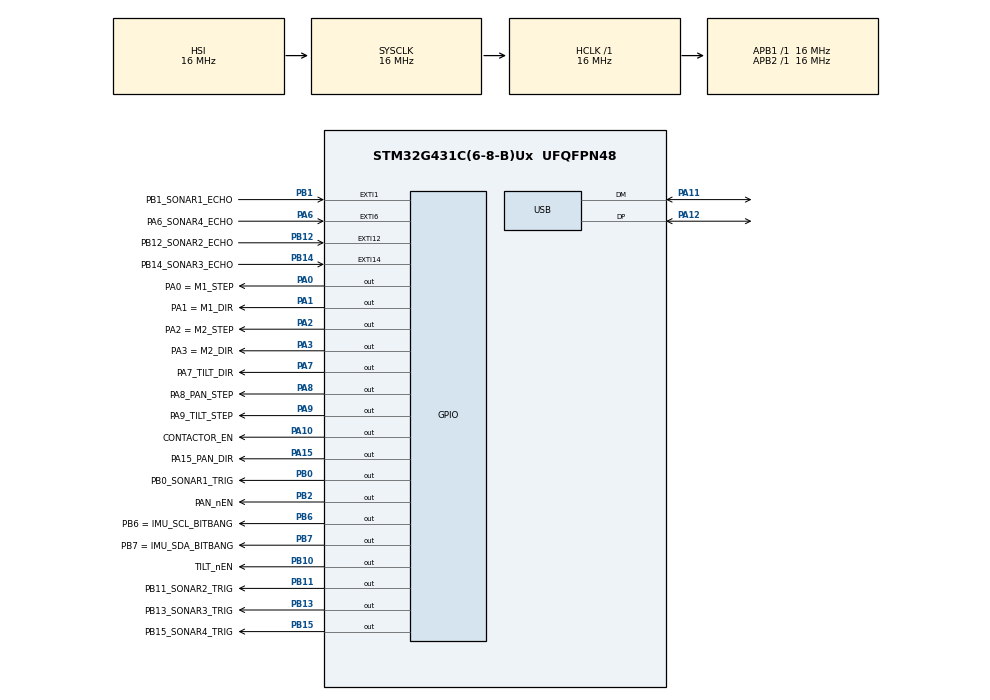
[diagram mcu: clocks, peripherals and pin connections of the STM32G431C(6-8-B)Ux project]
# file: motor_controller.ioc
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Mcu.Family=STM32G4
Mcu.Name=STM32G431C(6-8-B)Ux
Mcu.Package=UFQFPN48
NVIC.EXTI15_10_IRQn=true\:2\:0\:false\:false\:true\:true\:true\:true
NVIC.EXTI1_IRQn=true\:2\:0\:false\:false\:true\:true\:true\:true
NVIC.EXTI9_5_IRQn=true\:2\:0\:false\:false\:true\:true\:true\:true
NVIC.PriorityGroup=NVIC_PRIORITYGROUP_4
NVIC.USB_LP_IRQn=true\:0\:0\:false\:false\:true\:false\:true\:true
PA0.GPIO_Label=PA0 \= M1_STEP
PA0.Signal=GPIO_Output
PA10.GPIO_Label=CONTACTOR_EN
PA10.Signal=GPIO_Output
PA1.GPIO_Label=PA1 \= M1_DIR
PA1.Signal=GPIO_Output
PA11.Mode=Device
PA11.Signal=USB_DM
PA12.Mode=Device
PA12.Signal=USB_DP
PA13.Mode=Serial_Wire
PA13.Signal=SYS_JTMS-SWDIO
PA14.Mode=Serial_Wire
PA14.Signal=SYS_JTCK-SWCLK
PA15.GPIO_Label=PA15_PAN_DIR
PA15.Signal=GPIO_Output
PA2.GPIO_Label=PA2 \= M2_STEP
PA2.Signal=GPIO_Output
PA3.GPIO_Label=PA3 \= M2_DIR
PA3.Signal=GPIO_Output
PA6.GPIO_Label=PA6_SONAR4_ECHO
PA6.GPIO_ModeDefaultEXTI=GPIO_MODE_IT_RISING_FALLING
PA6.GPIO_PuPd=GPIO_PULLDOWN
PA6.Signal=GPXTI6
PA7.GPIO_Label=PA7_TILT_DIR
PA7.Signal=GPIO_Output
PA8.GPIO_Label=PA8_PAN_STEP
PA8.Signal=GPIO_Output
PA9.GPIO_Label=PA9_TILT_STEP
PA9.Signal=GPIO_Output
PB0.GPIO_Label=PB0_SONAR1_TRIG
PB0.Signal=GPIO_Output
PB1.GPIO_Label=PB1_SONAR1_ECHO
PB1.GPIO_ModeDefaultEXTI=GPIO_MODE_IT_RISING_FALLING
PB1.GPIO_PuPd=GPIO_PULLDOWN
PB1.Signal=GPXTI1
PB11.GPIO_Label=PB11_SONAR2_TRIG
PB11.Signal=GPIO_Output
PB12.GPIO_Label=PB12_SONAR2_ECHO
PB12.GPIO_ModeDefaultEXTI=GPIO_MODE_IT_RISING_FALLING
PB12.GPIO_PuPd=GPIO_PULLDOWN
PB12.Signal=GPXTI12
PB13.GPIO_Label=PB13_SONAR3_TRIG
PB13.Signal=GPIO_Output
PB14.GPIO_Label=PB14_SONAR3_ECHO
PB14.GPIO_ModeDefaultEXTI=GPIO_MODE_IT_RISING_FALLING
PB14.GPIO_PuPd=GPIO_PULLDOWN
PB14.Signal=GPXTI14
PB15.GPIO_Label=PB15_SONAR4_TRIG
PB15.Signal=GPIO_Output
PB2.GPIO_Label=PAN_nEN
PB2.PinState=GPIO_PIN_SET
PB2.Signal=GPIO_Output
PB6.GPIO_Label=PB6 \= IMU_SCL_BITBANG
PB6.Signal=GPIO_Output
PB7.GPIO_Label=PB7 \= IMU_SDA_BITBANG
PB7.Signal=GPIO_Output
PB10.GPIO_Label=TILT_nEN
PB10.GPIO_PuPd=GPIO_NOPULL
PB10.GPIO_Speed=GPIO_SPEED_FREQ_LOW
PB10.PinState=GPIO_PIN_SET
PB10.Signal=GPIO_Output
ProjectManager.HeapSize=0x200
ProjectManager.StackSize=0x400
ProjectManager.TargetToolchain=STM32CubeIDE
RCC.AHBFreq_Value=16000000
RCC.APB1Freq_Value=16000000
RCC.APB1TimFreq_Value=16000000
RCC.APB2Freq_Value=16000000
RCC.APB2TimFreq_Value=16000000
RCC.CortexFreq_Value=16000000
RCC.EXTERNAL_CLOCK_VALUE=12288000
RCC.HCLKFreq_Value=16000000
RCC.HSE_VALUE=8000000
RCC.HSI48_VALUE=48000000
RCC.HSI_VALUE=16000000
RCC.LSE_VALUE=32768
RCC.PLLN=12
RCC.PLLQ=RCC_PLLQ_DIV4
RCC.SYSCLKFreq_VALUE=16000000
RCC.USBFreq_Value=48000000
RCC.VCOOutputFreq_Value=192000000
TIM2.PeriodNoDither=19
TIM2.Prescaler=15
USB_DEVICE.CLASS_NAME_FS=CDC
USB_DEVICE.VirtualMode=Cdc
USB_DEVICE.VirtualModeFS=Cdc_FS
VP_SYS_VS_DBSignals.Mode=DisableDeadBatterySignals
VP_TIM2_VS_ClockSourceINT.Mode=Internal
VP_USB_DEVICE_VS_USB_DEVICE_CDC_FS.Mode=CDC_FS
board=custom

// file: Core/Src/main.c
/* USER CODE BEGIN Header */
/**
  ******************************************************************************
  * @file           : main.c
  * @brief          : Main program body
  ******************************************************************************
  * @attention
  *
  * Copyright (c) 2026 STMicroelectronics.
  * All rights reserved.
  *
  * This software is licensed under terms that can be found in the LICENSE file
  * in the root directory of this software component.
  * If no LICENSE file comes with this software, it is provided AS-IS.
  *
  ******************************************************************************
  */
/* USER CODE END Header */
#include "main.h"
#include "usb_device.h"

/* USER CODE BEGIN Includes */
#include "app/app.h"
#include "sonar/sr04t.h"
/* USER CODE END Includes */

TIM_HandleTypeDef htim2;

void SystemClock_Config(void);
static void MX_GPIO_Init(void);
static void MX_TIM2_Init(void);

int main(void)
{

  /* MCU Configuration--------------------------------------------------------*/

  /* Reset of all peripherals, Initializes the Flash interface and the Systick. */
  HAL_Init();

  /* Configure the system clock */
  SystemClock_Config();

  /* Initialize all configured peripherals */
  MX_GPIO_Init();
  MX_USB_Device_Init();
  MX_TIM2_Init();
  /* USER CODE BEGIN 2 */
  App_Init();
  SR04T_Init();
  /* USER CODE END 2 */

  /* Infinite loop */
  while (1)
  {

    /* USER CODE BEGIN 3 */
    App_Loop();
  }
  /* USER CODE END 3 */
}

void SystemClock_Config(void)
{
  RCC_OscInitTypeDef RCC_OscInitStruct = {0};
  RCC_ClkInitTypeDef RCC_ClkInitStruct = {0};

  /** Configure the main internal regulator output voltage
  */
  HAL_PWREx_ControlVoltageScaling(PWR_REGULATOR_VOLTAGE_SCALE1);

  /** Initializes the RCC Oscillators according to the specified parameters
  * in the RCC_OscInitTypeDef structure.
  */
  RCC_OscInitStruct.OscillatorType = RCC_OSCILLATORTYPE_HSI;
  RCC_OscInitStruct.HSIState = RCC_HSI_ON;
  RCC_OscInitStruct.HSICalibrationValue = RCC_HSICALIBRATION_DEFAULT;
  RCC_OscInitStruct.PLL.PLLState = RCC_PLL_ON;
  RCC_OscInitStruct.PLL.PLLSource = RCC_PLLSOURCE_HSI;
  RCC_OscInitStruct.PLL.PLLM = RCC_PLLM_DIV1;
  RCC_OscInitStruct.PLL.PLLN = 12;
  RCC_OscInitStruct.PLL.PLLP = RCC_PLLP_DIV2;
  RCC_OscInitStruct.PLL.PLLQ = RCC_PLLQ_DIV4;
  RCC_OscInitStruct.PLL.PLLR = RCC_PLLR_DIV2;
  if (HAL_RCC_OscConfig(&RCC_OscInitStruct) != HAL_OK)
  {
    Error_Handler();
  }

  /** Initializes the CPU, AHB and APB buses clocks
  */
  RCC_ClkInitStruct.ClockType = RCC_CLOCKTYPE_HCLK|RCC_CLOCKTYPE_SYSCLK
                              |RCC_CLOCKTYPE_PCLK1|RCC_CLOCKTYPE_PCLK2;
  RCC_ClkInitStruct.SYSCLKSource = RCC_SYSCLKSOURCE_HSI;
  RCC_ClkInitStruct.AHBCLKDivider = RCC_SYSCLK_DIV1;
  RCC_ClkInitStruct.APB1CLKDivider = RCC_HCLK_DIV1;
  RCC_ClkInitStruct.APB2CLKDivider = RCC_HCLK_DIV1;

  if (HAL_RCC_ClockConfig(&RCC_ClkInitStruct, FLASH_LATENCY_0) != HAL_OK)
  {
    Error_Handler();
  }
}

static void MX_TIM2_Init(void)
{

  TIM_ClockConfigTypeDef sClockSourceConfig = {0};
  TIM_MasterConfigTypeDef sMasterConfig = {0};

  htim2.Instance = TIM2;
  htim2.Init.Prescaler = 15;
  htim2.Init.CounterMode = TIM_COUNTERMODE_UP;
  htim2.Init.Period = 19;
  htim2.Init.ClockDivision = TIM_CLOCKDIVISION_DIV1;
  htim2.Init.AutoReloadPreload = TIM_AUTORELOAD_PRELOAD_DISABLE;
  if (HAL_TIM_Base_Init(&htim2) != HAL_OK)
  {
    Error_Handler();
  }
  sClockSourceConfig.ClockSource = TIM_CLOCKSOURCE_INTERNAL;
  if (HAL_TIM_ConfigClockSource(&htim2, &sClockSourceConfig) != HAL_OK)
  {
    Error_Handler();
  }
  sMasterConfig.MasterOutputTrigger = TIM_TRGO_RESET;
  sMasterConfig.MasterSlaveMode = TIM_MASTERSLAVEMODE_DISABLE;
  if (HAL_TIMEx_MasterConfigSynchronization(&htim2, &sMasterConfig) != HAL_OK)
  {
    Error_Handler();
  }

}

static void MX_GPIO_Init(void)
{
  GPIO_InitTypeDef GPIO_InitStruct = {0};

  /* GPIO Ports Clock Enable */
  __HAL_RCC_GPIOA_CLK_ENABLE();
  __HAL_RCC_GPIOB_CLK_ENABLE();

  /*Configure GPIO pin Output Level */
  HAL_GPIO_WritePin(GPIOA, PA0___M1_STEP_Pin|PA1___M1_DIR_Pin|PA2___M2_STEP_Pin|PA3___M2_DIR_Pin
                          |PA7_TILT_DIR_Pin|PA8_PAN_STEP_Pin|PA9_TILT_STEP_Pin|CONTACTOR_EN_Pin
                          |PA15_PAN_DIR_Pin, GPIO_PIN_RESET);

  /*Configure GPIO pin Output Level */
  HAL_GPIO_WritePin(GPIOB, PB0_SONAR1_TRIG_Pin|PB11_SONAR2_TRIG_Pin|PB13_SONAR3_TRIG_Pin|PB15_SONAR4_TRIG_Pin|PB6___IMU_SCL_BITBANG_Pin|PB7___IMU_SDA_BITBANG_Pin, GPIO_PIN_RESET);

  /*Configure GPIO pin Output Level */
  HAL_GPIO_WritePin(GPIOB, PAN_nEN_Pin|TILT_nEN_Pin, GPIO_PIN_SET);

  /*Configure GPIO pins : PA0___M1_STEP_Pin PA1___M1_DIR_Pin PA2___M2_STEP_Pin PA3___M2_DIR_Pin
                           PA7_TILT_DIR_Pin PA8_PAN_STEP_Pin PA9_TILT_STEP_Pin CONTACTOR_EN_Pin
                           PA15_PAN_DIR_Pin */
  GPIO_InitStruct.Pin = PA0___M1_STEP_Pin|PA1___M1_DIR_Pin|PA2___M2_STEP_Pin|PA3___M2_DIR_Pin
                          |PA7_TILT_DIR_Pin|PA8_PAN_STEP_Pin|PA9_TILT_STEP_Pin|CONTACTOR_EN_Pin
                          |PA15_PAN_DIR_Pin;
  GPIO_InitStruct.Mode = GPIO_MODE_OUTPUT_PP;
  GPIO_InitStruct.Pull = GPIO_NOPULL;
  GPIO_InitStruct.Speed = GPIO_SPEED_FREQ_LOW;
  HAL_GPIO_Init(GPIOA, &GPIO_InitStruct);

  /*Configure GPIO pins : PB0_SONAR1_TRIG_Pin PB11_SONAR2_TRIG_Pin PB13_SONAR3_TRIG_Pin PB15_SONAR4_TRIG_Pin PB6___IMU_SCL_BITBANG_Pin PB7___IMU_SDA_BITBANG_Pin PAN_nEN_Pin TILT_nEN_Pin */
  GPIO_InitStruct.Pin = PB0_SONAR1_TRIG_Pin|PB11_SONAR2_TRIG_Pin|PB13_SONAR3_TRIG_Pin|PB15_SONAR4_TRIG_Pin|PB6___IMU_SCL_BITBANG_Pin|PB7___IMU_SDA_BITBANG_Pin|PAN_nEN_Pin|TILT_nEN_Pin;
  GPIO_InitStruct.Mode = GPIO_MODE_OUTPUT_PP;
  GPIO_InitStruct.Pull = GPIO_NOPULL;
  GPIO_InitStruct.Speed = GPIO_SPEED_FREQ_LOW;
  HAL_GPIO_Init(GPIOB, &GPIO_InitStruct);

  /*Configure GPIO pins : PB1_SONAR1_ECHO_Pin PB12_SONAR2_ECHO_Pin PB14_SONAR3_ECHO_Pin */
  /* PULLDOWN (khong phai NOPULL): chan ECHO cua SR04T nghi o muc thap va phat
     xung len cao. De tha noi thi khi chua cam cam bien (hoac dut day, hoac cam
     bien chet) chan bat nhieu, EXTI hai suon sinh xung ngau nhien, va driver
     tinh ra khoang cach "hop ly" roi gan co valid=1 -- vat can ma di thang vao
     local costmap cua Nav2 ma khong co dau hieu loi nao.
     Cam bien that co ngo ra push-pull, thang dien tro noi ~40k de dang, nen
     phep do khong bi anh huong. Gia tri nay cung da duoc sua trong .ioc. */
  GPIO_InitStruct.Pin = PB1_SONAR1_ECHO_Pin|PB12_SONAR2_ECHO_Pin|PB14_SONAR3_ECHO_Pin;
  GPIO_InitStruct.Mode = GPIO_MODE_IT_RISING_FALLING;
  GPIO_InitStruct.Pull = GPIO_PULLDOWN;
  HAL_GPIO_Init(GPIOB, &GPIO_InitStruct);

  /*Configure GPIO pin : PA6_SONAR4_ECHO_Pin */
  GPIO_InitStruct.Pin = PA6_SONAR4_ECHO_Pin;
  GPIO_InitStruct.Mode = GPIO_MODE_IT_RISING_FALLING;
  GPIO_InitStruct.Pull = GPIO_PULLDOWN;
  HAL_GPIO_Init(GPIOA, &GPIO_InitStruct);

  /* EXTI interrupt init*/
  HAL_NVIC_SetPriority(EXTI1_IRQn, 2, 0);
  HAL_NVIC_EnableIRQ(EXTI1_IRQn);

  HAL_NVIC_SetPriority(EXTI9_5_IRQn, 2, 0);
  HAL_NVIC_EnableIRQ(EXTI9_5_IRQn);

  HAL_NVIC_SetPriority(EXTI15_10_IRQn, 2, 0);
  HAL_NVIC_EnableIRQ(EXTI15_10_IRQn);

}

void Error_Handler(void)
{
  __disable_irq();
  while (1)
  {
  }
}
